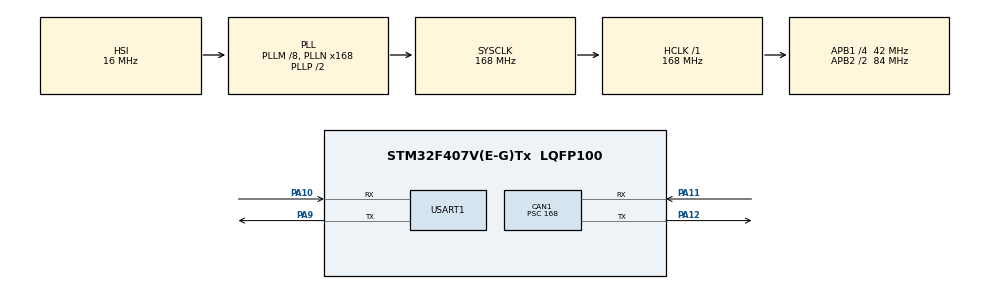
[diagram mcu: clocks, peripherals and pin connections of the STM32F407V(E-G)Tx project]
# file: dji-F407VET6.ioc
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CAN1.BS1=CAN_BS1_16TQ
CAN1.BS2=CAN_BS2_8TQ
CAN1.CalculateBaudRate=10000
CAN1.CalculateTimeBit=100000
CAN1.CalculateTimeQuantum=4000.0
CAN1.Mode=CAN_MODE_LOOPBACK
CAN1.Prescaler=168
Dma.Request0=USART1_TX
Dma.USART1_TX.0.Direction=DMA_MEMORY_TO_PERIPH
Dma.USART1_TX.0.FIFOMode=DMA_FIFOMODE_DISABLE
Dma.USART1_TX.0.Instance=DMA2_Stream7
Dma.USART1_TX.0.MemDataAlignment=DMA_MDATAALIGN_BYTE
Dma.USART1_TX.0.MemInc=DMA_MINC_ENABLE
Dma.USART1_TX.0.Mode=DMA_NORMAL
Dma.USART1_TX.0.PeriphDataAlignment=DMA_PDATAALIGN_BYTE
Dma.USART1_TX.0.PeriphInc=DMA_PINC_DISABLE
Dma.USART1_TX.0.Priority=DMA_PRIORITY_LOW
Mcu.Family=STM32F4
Mcu.Name=STM32F407V(E-G)Tx
Mcu.Package=LQFP100
NVIC.CAN1_RX0_IRQn=true\:0\:0\:false\:false\:true\:true\:true\:true
NVIC.CAN1_RX1_IRQn=true\:0\:0\:false\:false\:true\:true\:true\:true
NVIC.CAN1_SCE_IRQn=true\:0\:0\:false\:false\:true\:true\:true\:true
NVIC.CAN1_TX_IRQn=true\:0\:0\:false\:false\:true\:true\:true\:true
NVIC.DMA2_Stream7_IRQn=true\:0\:0\:false\:false\:true\:false\:true\:true
NVIC.PriorityGroup=NVIC_PRIORITYGROUP_4
PA10.Mode=Asynchronous
PA10.Signal=USART1_RX
PA11.Mode=CAN_Activate
PA11.Signal=CAN1_RX
PA12.Mode=CAN_Activate
PA12.Signal=CAN1_TX
PA13.Mode=Serial_Wire
PA13.Signal=SYS_JTMS-SWDIO
PA14.Mode=Serial_Wire
PA14.Signal=SYS_JTCK-SWCLK
PA9.Mode=Asynchronous
PA9.Signal=USART1_TX
PH0-OSC_IN.Mode=HSE-External-Oscillator
PH0-OSC_IN.Signal=RCC_OSC_IN
PH1-OSC_OUT.Mode=HSE-External-Oscillator
PH1-OSC_OUT.Signal=RCC_OSC_OUT
ProjectManager.HeapSize=0x200
ProjectManager.StackSize=0x400
ProjectManager.TargetToolchain=Makefile
RCC.48MHZClocksFreq_Value=84000000
RCC.AHBFreq_Value=168000000
RCC.APB1CLKDivider=RCC_HCLK_DIV4
RCC.APB1Freq_Value=42000000
RCC.APB1TimFreq_Value=84000000
RCC.APB2CLKDivider=RCC_HCLK_DIV2
RCC.APB2Freq_Value=84000000
RCC.APB2TimFreq_Value=168000000
RCC.CortexFreq_Value=168000000
RCC.HCLKFreq_Value=168000000
RCC.HSE_VALUE=25000000
RCC.HSI_VALUE=16000000
RCC.LSE_VALUE=32768
RCC.PLLM=8
RCC.PLLN=168
RCC.SYSCLKFreq_VALUE=168000000
RCC.SYSCLKSource=RCC_SYSCLKSOURCE_PLLCLK
RCC.VCOOutputFreq_Value=336000000
USART1.VirtualMode=VM_ASYNC
board=custom

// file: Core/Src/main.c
/* USER CODE BEGIN Header */
/**
  ******************************************************************************
  * @file           : main.c
  * @brief          : Main program body
  ******************************************************************************
  * @attention
  *
  * Copyright (c) 2026 STMicroelectronics.
  * All rights reserved.
  *
  * This software is licensed under terms that can be found in the LICENSE file
  * in the root directory of this software component.
  * If no LICENSE file comes with this software, it is provided AS-IS.
  *
  ******************************************************************************
  */
/* USER CODE END Header */
#include "main.h"
#include "can.h"
#include "dma.h"
#include "usart.h"
#include "gpio.h"

/* USER CODE BEGIN Includes */
#include "can_motor.h"// 包含 CAN 电机控制的头文件
#include "motor_control.h" // 包含电机控制策略的头文件
#include "debug_monitor.h" // 包含调试监控模块的头文件
#include "vofa.h" // 包含 VOFA 发送功能的头文件
/* USER CODE END Includes */

/* USER CODE BEGIN PV */

int16_t motor_iq[4] = {0}; // 全局电流指令数组，供调试监控模块访问

/* USER CODE END PV */

void SystemClock_Config(void);

int main(void)
{

  /* MCU Configuration--------------------------------------------------------*/

  /* Reset of all peripherals, Initializes the Flash interface and the Systick. */
  HAL_Init();

  /* USER CODE BEGIN Init */
  VOFA_Init(); // 初始化 VOFA 发送功能
  /* USER CODE END Init */

  /* Configure the system clock */
  SystemClock_Config();

  /* Initialize all configured peripherals */
  MX_GPIO_Init();
  MX_DMA_Init();
  MX_CAN1_Init();
  MX_USART1_UART_Init();

  /* USER CODE BEGIN 2 */
  CAN_Motor_Init();  // 初始化 CAN 电机控制模块
  HAL_CAN_ActivateNotification(&hcan1, CAN_IT_RX_FIFO0_MSG_PENDING); // 激活 CAN 接收中断，接收消息后会更新 motor_data 数组
  Debug_Monitor_Init(); // 初始化调试监控模块
  /* USER CODE END 2 */

  /* Infinite loop */
  while (1)
  {

    /* USER CODE BEGIN 3 */

    CAN_Motor_UpdateOnlineStatus(); // 1.定期检查电机在线状态

    Motor_Control_Update(motor_data); // 2.根据电机状态更新控制策略，计算目标电流并写入 motor_iq 数组

    CAN_Motor_SendCurrent(motor_iq);  // 3.发送电流指令给电机

    Debug_Monitor_Update(); // 4.更新调试监控数据并发送到 VOFA+

    HAL_Delay(2); // 5.约(2ms) 500Hz 发送频率，足够稳定

  }
  /* USER CODE END 3 */
}

void SystemClock_Config(void)
{
  RCC_OscInitTypeDef RCC_OscInitStruct = {0};
  RCC_ClkInitTypeDef RCC_ClkInitStruct = {0};

  /** Configure the main internal regulator output voltage
  */
  __HAL_RCC_PWR_CLK_ENABLE();
  __HAL_PWR_VOLTAGESCALING_CONFIG(PWR_REGULATOR_VOLTAGE_SCALE1);

  /** Initializes the RCC Oscillators according to the specified parameters
  * in the RCC_OscInitTypeDef structure.
  */
  RCC_OscInitStruct.OscillatorType = RCC_OSCILLATORTYPE_HSI;
  RCC_OscInitStruct.HSIState = RCC_HSI_ON;
  RCC_OscInitStruct.HSICalibrationValue = RCC_HSICALIBRATION_DEFAULT;
  RCC_OscInitStruct.PLL.PLLState = RCC_PLL_ON;
  RCC_OscInitStruct.PLL.PLLSource = RCC_PLLSOURCE_HSI;
  RCC_OscInitStruct.PLL.PLLM = 8;
  RCC_OscInitStruct.PLL.PLLN = 168;
  RCC_OscInitStruct.PLL.PLLP = RCC_PLLP_DIV2;
  RCC_OscInitStruct.PLL.PLLQ = 4;
  if (HAL_RCC_OscConfig(&RCC_OscInitStruct) != HAL_OK)
  {
    Error_Handler();
  }

  /** Initializes the CPU, AHB and APB buses clocks
  */
  RCC_ClkInitStruct.ClockType = RCC_CLOCKTYPE_HCLK|RCC_CLOCKTYPE_SYSCLK
                              |RCC_CLOCKTYPE_PCLK1|RCC_CLOCKTYPE_PCLK2;
  RCC_ClkInitStruct.SYSCLKSource = RCC_SYSCLKSOURCE_PLLCLK;
  RCC_ClkInitStruct.AHBCLKDivider = RCC_SYSCLK_DIV1;
  RCC_ClkInitStruct.APB1CLKDivider = RCC_HCLK_DIV4;
  RCC_ClkInitStruct.APB2CLKDivider = RCC_HCLK_DIV2;

  if (HAL_RCC_ClockConfig(&RCC_ClkInitStruct, FLASH_LATENCY_5) != HAL_OK)
  {
    Error_Handler();
  }
}

void Error_Handler(void)
{
  __disable_irq();
  while (1)
  {
  }
}
